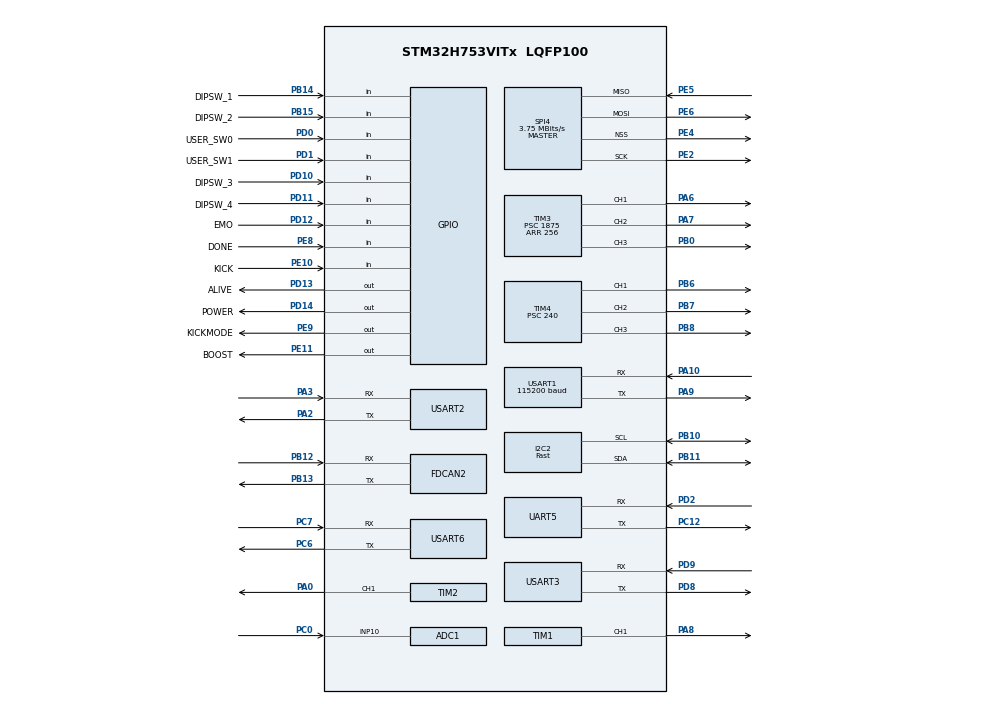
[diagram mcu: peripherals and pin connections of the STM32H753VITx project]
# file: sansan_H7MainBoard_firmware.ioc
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ADC1.Channel-3\#ChannelRegularConversion=ADC_CHANNEL_10
ADC1.ContinuousConvMode=DISABLE
ADC1.NbrOfConversionFlag=1
ADC1.OffsetNumber-3\#ChannelRegularConversion=ADC_OFFSET_NONE
ADC1.Rank-3\#ChannelRegularConversion=1
ADC1.Resolution=ADC_RESOLUTION_10B
ADC1.SamplingTime-3\#ChannelRegularConversion=ADC_SAMPLETIME_1CYCLE_5
ADC1.master=1
Dma.Request0=UART5_RX
Dma.UART5_RX.0.Direction=DMA_PERIPH_TO_MEMORY
Dma.UART5_RX.0.EventEnable=DISABLE
Dma.UART5_RX.0.FIFOMode=DMA_FIFOMODE_DISABLE
Dma.UART5_RX.0.Instance=DMA1_Stream0
Dma.UART5_RX.0.MemDataAlignment=DMA_MDATAALIGN_BYTE
Dma.UART5_RX.0.MemInc=DMA_MINC_ENABLE
Dma.UART5_RX.0.Mode=DMA_CIRCULAR
Dma.UART5_RX.0.PeriphDataAlignment=DMA_PDATAALIGN_BYTE
Dma.UART5_RX.0.PeriphInc=DMA_PINC_DISABLE
Dma.UART5_RX.0.Polarity=HAL_DMAMUX_REQ_GEN_RISING
Dma.UART5_RX.0.Priority=DMA_PRIORITY_LOW
Dma.UART5_RX.0.RequestNumber=1
Dma.UART5_RX.0.SignalID=NONE
Dma.UART5_RX.0.SyncEnable=DISABLE
Dma.UART5_RX.0.SyncPolarity=HAL_DMAMUX_SYNC_NO_EVENT
Dma.UART5_RX.0.SyncRequestNumber=1
Dma.UART5_RX.0.SyncSignalID=NONE
FDCAN2.DataPrescaler=8
FDCAN2.DataSyncJumpWidth=2
FDCAN2.DataTimeSeg1=6
FDCAN2.DataTimeSeg2=3
FDCAN2.MessageRAMOffset=500
FDCAN2.NominalPrescaler=8
FDCAN2.NominalSyncJumpWidth=2
FDCAN2.NominalTimeSeg1=6
FDCAN2.NominalTimeSeg2=3
FDCAN2.RxFifo0ElmtsNbr=32
FDCAN2.StdFiltersNbr=1
FDCAN2.TxBuffersNbr=16
FDCAN2.TxFifoQueueElmtsNbr=16
I2C2.I2C_Fall_Time=300
I2C2.I2C_Rise_Time=300
I2C2.I2C_Speed_Mode=I2C_Fast
I2C2.Timing=0x30B70F24
Mcu.Family=STM32H7
Mcu.Name=STM32H753VITx
Mcu.Package=LQFP100
NVIC.DMA1_Stream0_IRQn=true\:0\:0\:false\:false\:true\:false\:true\:true
NVIC.FDCAN2_IT0_IRQn=true\:1\:0\:true\:false\:true\:true\:true\:true
NVIC.FDCAN2_IT1_IRQn=true\:1\:0\:true\:false\:true\:true\:true\:true
NVIC.PriorityGroup=NVIC_PRIORITYGROUP_4
NVIC.SPI4_IRQn=true\:0\:0\:false\:false\:true\:true\:true\:true
NVIC.TIM8_BRK_TIM12_IRQn=true\:0\:0\:false\:false\:true\:true\:true\:true
NVIC.TIM8_UP_TIM13_IRQn=true\:2\:0\:true\:false\:true\:true\:true\:true
NVIC.UART5_IRQn=true\:3\:0\:true\:false\:true\:true\:true\:true
NVIC.USART1_IRQn=true\:0\:0\:false\:false\:true\:true\:true\:true
PA0.Signal=S_TIM2_CH1
PA10.Mode=Asynchronous
PA10.Signal=USART1_RX
PA13\ (JTMS/SWDIO).Mode=Trace_Asynchronous_SW
PA13\ (JTMS/SWDIO).Signal=DEBUG_JTMS-SWDIO
PA14\ (JTCK/SWCLK).Mode=Trace_Asynchronous_SW
PA14\ (JTCK/SWCLK).Signal=DEBUG_JTCK-SWCLK
PA2.Mode=Asynchronous
PA2.Signal=USART2_TX
PA3.Mode=Asynchronous
PA3.Signal=USART2_RX
PA6.Signal=S_TIM3_CH1
PA7.Signal=S_TIM3_CH2
PA8.Signal=S_TIM1_CH1
PA9.Mode=Asynchronous
PA9.Signal=USART1_TX
PB0.Signal=S_TIM3_CH3
PB10.Mode=I2C
PB10.Signal=I2C2_SCL
PB11.Mode=I2C
PB11.Signal=I2C2_SDA
PB12.Mode=FDCAN_Activate
PB12.Signal=FDCAN2_RX
PB13.Mode=FDCAN_Activate
PB13.Signal=FDCAN2_TX
PB14.GPIO_Label=DIPSW_1
PB14.GPIO_PuPd=GPIO_PULLUP
PB14.Signal=GPIO_Input
PB15.GPIO_Label=DIPSW_2
PB15.GPIO_PuPd=GPIO_PULLUP
PB15.Signal=GPIO_Input
PB3\ (JTDO/TRACESWO).Mode=Trace_Asynchronous_SW
PB3\ (JTDO/TRACESWO).Signal=DEBUG_JTDO-SWO
PB6.Signal=S_TIM4_CH1
PB7.Signal=S_TIM4_CH2
PB8.Signal=S_TIM4_CH3
PC0.Signal=ADCx_INP10
PC12.Mode=Asynchronous
PC12.Signal=UART5_TX
PC6.Mode=Asynchronous
PC6.Signal=USART6_TX
PC7.Mode=Asynchronous
PC7.Signal=USART6_RX
PD0.GPIO_Label=USER_SW0
PD0.GPIO_PuPd=GPIO_PULLUP
PD0.Signal=GPIO_Input
PD1.GPIO_Label=USER_SW1
PD1.GPIO_PuPd=GPIO_PULLUP
PD1.Signal=GPIO_Input
PD10.GPIO_Label=DIPSW_3
PD10.GPIO_PuPd=GPIO_PULLUP
PD10.Signal=GPIO_Input
PD11.GPIO_Label=DIPSW_4
PD11.GPIO_PuPd=GPIO_PULLUP
PD11.Signal=GPIO_Input
PD12.GPIO_Label=EMO
PD12.Signal=GPIO_Input
PD13.GPIO_Label=ALIVE
PD13.Signal=GPIO_Output
PD14.GPIO_Label=POWER
PD14.Signal=GPIO_Output
PD2.Mode=Asynchronous
PD2.Signal=UART5_RX
PD8.Mode=Asynchronous
PD8.Signal=USART3_TX
PD9.Mode=Asynchronous
PD9.Signal=USART3_RX
PE0.Signal=UART8_RX
PE1.Signal=UART8_TX
PE10.GPIO_Label=KICK
PE10.Signal=GPIO_Input
PE11.GPIO_Label=BOOST
PE11.Signal=GPIO_Output
PE2.Mode=Full_Duplex_Master
PE2.Signal=SPI4_SCK
PE4.GPIO_PuPd=GPIO_PULLUP
PE4.Mode=NSS_Signal_Hard_Output
PE4.Signal=SPI4_NSS
PE5.Mode=Full_Duplex_Master
PE5.Signal=SPI4_MISO
PE6.Mode=Full_Duplex_Master
PE6.Signal=SPI4_MOSI
PE8.GPIO_Label=DONE
PE8.Signal=GPIO_Input
PE9.GPIO_Label=KICKMODE
PE9.Signal=GPIO_Output
PH0-OSC_IN\ (PH0).Mode=HSE-External-Oscillator
PH0-OSC_IN\ (PH0).Signal=RCC_OSC_IN
PH1-OSC_OUT\ (PH1).Mode=HSE-External-Oscillator
PH1-OSC_OUT\ (PH1).Signal=RCC_OSC_OUT
ProjectManager.HeapSize=0x200
ProjectManager.StackSize=0x400
ProjectManager.TargetToolchain=STM32CubeIDE
RCC.ADCFreq_Value=80000000
RCC.APB1Freq_Value=120000000
RCC.APB2Freq_Value=120000000
RCC.APB3Freq_Value=120000000
RCC.APB4Freq_Value=120000000
RCC.CortexFreq_Value=480000000
RCC.D1PPRE=RCC_APB3_DIV2
RCC.D2PPRE1=RCC_APB1_DIV2
RCC.D2PPRE2=RCC_APB2_DIV2
RCC.D3PPRE=RCC_APB4_DIV2
RCC.DIVM1=8
RCC.DIVM2=8
RCC.DIVN1=480
RCC.DIVN2=80
RCC.DIVQ3=4
RCC.DIVR3=4
RCC.FDCANCLockSelection=RCC_FDCANCLKSOURCE_PLL2
RCC.HCLKFreq_Value=240000000
RCC.HPRE=RCC_HCLK_DIV2
RCC.HSE_VALUE=16000000
RCC.PLLFRACN=0
RCC.PLLSourceVirtual=RCC_PLLSOURCE_HSE
RCC.ProductRev=revV
RCC.SYSCLKFreq_VALUE=480000000
RCC.SYSCLKSource=RCC_SYSCLKSOURCE_PLLCLK
RCC.USBFreq_Value=480000000
SH.ADCx_INP10.0=ADC1_INP10,IN10-Single-Ended
SH.S_TIM1_CH1.0=TIM1_CH1,PWM Generation1 CH1
SH.S_TIM2_CH1.0=TIM2_CH1,PWM Generation1 CH1
SH.S_TIM3_CH1.0=TIM3_CH1,PWM Generation1 CH1
SH.S_TIM3_CH2.0=TIM3_CH2,PWM Generation2 CH2
SH.S_TIM3_CH3.0=TIM3_CH3,PWM Generation3 CH3
SH.S_TIM4_CH1.0=TIM4_CH1,PWM Generation1 CH1
SH.S_TIM4_CH2.0=TIM4_CH2,PWM Generation2 CH2
SH.S_TIM4_CH3.0=TIM4_CH3,PWM Generation3 CH3
SPI4.BaudRatePrescaler=SPI_BAUDRATEPRESCALER_32
SPI4.CalculateBaudRate=3.75 MBits/s
SPI4.DataSize=SPI_DATASIZE_8BIT
SPI4.Direction=SPI_DIRECTION_2LINES
SPI4.Mode=SPI_MODE_MASTER
SPI4.VirtualNSS=VM_NSSHARD
SPI4.VirtualType=VM_MASTER
TIM1.Channel-PWM\ Generation1\ CH1=TIM_CHANNEL_1
TIM1.Period=10000
TIM1.Prescaler=480
TIM1.Pulse-PWM\ Generation1\ CH1=0
TIM12.Period=240
TIM12.Prescaler=1000
TIM13.Period=2400
TIM13.Prescaler=1000
TIM2.Channel-PWM\ Generation1\ CH1=TIM_CHANNEL_1
TIM3.AutoReloadPreload=TIM_AUTORELOAD_PRELOAD_ENABLE
TIM3.Channel-PWM\ Generation1\ CH1=TIM_CHANNEL_1
TIM3.Channel-PWM\ Generation2\ CH2=TIM_CHANNEL_2
TIM3.Channel-PWM\ Generation3\ CH3=TIM_CHANNEL_3
TIM3.Period=256
TIM3.Prescaler=1875
TIM3.Pulse-PWM\ Generation1\ CH1=0
TIM3.Pulse-PWM\ Generation2\ CH2=0
TIM3.Pulse-PWM\ Generation3\ CH3=0
TIM4.Channel-PWM\ Generation1\ CH1=TIM_CHANNEL_1
TIM4.Channel-PWM\ Generation2\ CH2=TIM_CHANNEL_2
TIM4.Channel-PWM\ Generation3\ CH3=TIM_CHANNEL_3
TIM4.OC1Preload_PWM=ENABLE
TIM4.Prescaler=240
TIM4.Pulse-PWM\ Generation1\ CH1=0
USART1.BaudRate=115200
USART1.VirtualMode-Asynchronous=VM_ASYNC
USART2.VirtualMode-Asynchronous=VM_ASYNC
USART3.VirtualMode-Asynchronous=VM_ASYNC
USART6.FIFOMode=FIFOMODE_ENABLE
USART6.VirtualMode=VM_ASYNC
VP_TIM12_VS_ClockSourceINT.Mode=Internal
VP_TIM13_VS_ClockSourceINT.Mode=Enable_Timer
VP_TIM1_VS_ClockSourceINT.Mode=Internal
VP_TIM2_VS_ClockSourceINT.Mode=Internal
VP_TIM4_VS_ClockSourceINT.Mode=Internal
board=custom

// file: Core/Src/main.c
/* USER CODE BEGIN Header */
/**
  ******************************************************************************
  * @file           : main.c
  * @brief          : Main program body
  ******************************************************************************
  * @attention
  *
  * <h2><center>&copy; Copyright (c) 2020 STMicroelectronics.
  * All rights reserved.</center></h2>
  *
  * This software component is licensed by ST under BSD 3-Clause license,
  * the "License"; You may not use this file except in compliance with the
  * License. You may obtain a copy of the License at:
  *                        opensource.org/licenses/BSD-3-Clause
  *
  ******************************************************************************
  */
/* USER CODE END Header */
#include "main.h"

/* USER CODE BEGIN Includes */

#include <stdio.h>

#include "cppWrapper.hpp"

/* USER CODE END Includes */

ADC_HandleTypeDef hadc1;

FDCAN_HandleTypeDef hfdcan2;

I2C_HandleTypeDef hi2c2;

SPI_HandleTypeDef hspi4;

TIM_HandleTypeDef htim1;
TIM_HandleTypeDef htim2;
TIM_HandleTypeDef htim3;
TIM_HandleTypeDef htim4;
TIM_HandleTypeDef htim12;
TIM_HandleTypeDef htim13;

UART_HandleTypeDef huart5;
UART_HandleTypeDef huart1;
UART_HandleTypeDef huart2;
UART_HandleTypeDef huart3;
UART_HandleTypeDef huart6;
DMA_HandleTypeDef hdma_uart5_rx;
DMA_HandleTypeDef hdma_usart1_rx;

void SystemClock_Config(void);
void PeriphCommonClock_Config(void);
static void MX_GPIO_Init(void);
static void MX_DMA_Init(void);
static void MX_ADC1_Init(void);
static void MX_I2C2_Init(void);
static void MX_SPI4_Init(void);
static void MX_TIM1_Init(void);
static void MX_TIM2_Init(void);
static void MX_TIM3_Init(void);
static void MX_TIM4_Init(void);
static void MX_USART1_UART_Init(void);
static void MX_USART2_UART_Init(void);
static void MX_USART3_UART_Init(void);
static void MX_USART6_UART_Init(void);
static void MX_FDCAN2_Init(void);
static void MX_UART5_Init(void);
static void MX_TIM12_Init(void);
static void MX_TIM13_Init(void);

/* USER CODE BEGIN 0 */

#ifdef __GNUC__
#define PUTCHAR_PROTOTYPE int __io_putchar(int ch)
#else
#define PUTCHAR_PROTOTYPE int fputc(int ch, FILE *f)
#endif /* __GNUC__ */
void __io_putchar(uint8_t ch)
{
	HAL_UART_Transmit(&huart6, &ch, 1, 1);
}

/* USER CODE END 0 */

int main(void)
{

  /* MCU Configuration--------------------------------------------------------*/

  /* Reset of all peripherals, Initializes the Flash interface and the Systick. */
  HAL_Init();

  /* Configure the system clock */
  SystemClock_Config();

/* Configure the peripherals common clocks */
  PeriphCommonClock_Config();

  /* Initialize all configured peripherals */
  MX_GPIO_Init();
  MX_DMA_Init();
  MX_ADC1_Init();
  MX_I2C2_Init();
  MX_SPI4_Init();
  MX_TIM1_Init();
  MX_TIM2_Init();
  MX_TIM3_Init();
  MX_TIM4_Init();
  MX_USART1_UART_Init();
  MX_USART2_UART_Init();
  MX_USART3_UART_Init();
  MX_USART6_UART_Init();
  MX_FDCAN2_Init();
  MX_UART5_Init();
  MX_TIM12_Init();
  MX_TIM13_Init();
  /* USER CODE BEGIN 2 */

  cppMain();

  /* USER CODE END 2 */

  /* Infinite loop */
  while (1)
  {

  }
}

void SystemClock_Config(void)
{
  RCC_OscInitTypeDef RCC_OscInitStruct = {0};
  RCC_ClkInitTypeDef RCC_ClkInitStruct = {0};

  /** Supply configuration update enable
  */
  HAL_PWREx_ConfigSupply(PWR_LDO_SUPPLY);
  /** Configure the main internal regulator output voltage
  */
  __HAL_PWR_VOLTAGESCALING_CONFIG(PWR_REGULATOR_VOLTAGE_SCALE0);

  while(!__HAL_PWR_GET_FLAG(PWR_FLAG_VOSRDY)) {}
  /** Macro to configure the PLL clock source
  */
  __HAL_RCC_PLL_PLLSOURCE_CONFIG(RCC_PLLSOURCE_HSE);
  /** Initializes the RCC Oscillators according to the specified parameters
  * in the RCC_OscInitTypeDef structure.
  */
  RCC_OscInitStruct.OscillatorType = RCC_OSCILLATORTYPE_HSE;
  RCC_OscInitStruct.HSEState = RCC_HSE_ON;
  RCC_OscInitStruct.PLL.PLLState = RCC_PLL_ON;
  RCC_OscInitStruct.PLL.PLLSource = RCC_PLLSOURCE_HSE;
  RCC_OscInitStruct.PLL.PLLM = 8;
  RCC_OscInitStruct.PLL.PLLN = 480;
  RCC_OscInitStruct.PLL.PLLP = 2;
  RCC_OscInitStruct.PLL.PLLQ = 2;
  RCC_OscInitStruct.PLL.PLLR = 2;
  RCC_OscInitStruct.PLL.PLLRGE = RCC_PLL1VCIRANGE_1;
  RCC_OscInitStruct.PLL.PLLVCOSEL = RCC_PLL1VCOWIDE;
  RCC_OscInitStruct.PLL.PLLFRACN = 0;
  if (HAL_RCC_OscConfig(&RCC_OscInitStruct) != HAL_OK)
  {
    Error_Handler();
  }
  /** Initializes the CPU, AHB and APB buses clocks
  */
  RCC_ClkInitStruct.ClockType = RCC_CLOCKTYPE_HCLK|RCC_CLOCKTYPE_SYSCLK
                              |RCC_CLOCKTYPE_PCLK1|RCC_CLOCKTYPE_PCLK2
                              |RCC_CLOCKTYPE_D3PCLK1|RCC_CLOCKTYPE_D1PCLK1;
  RCC_ClkInitStruct.SYSCLKSource = RCC_SYSCLKSOURCE_PLLCLK;
  RCC_ClkInitStruct.SYSCLKDivider = RCC_SYSCLK_DIV1;
  RCC_ClkInitStruct.AHBCLKDivider = RCC_HCLK_DIV2;
  RCC_ClkInitStruct.APB3CLKDivider = RCC_APB3_DIV2;
  RCC_ClkInitStruct.APB1CLKDivider = RCC_APB1_DIV2;
  RCC_ClkInitStruct.APB2CLKDivider = RCC_APB2_DIV2;
  RCC_ClkInitStruct.APB4CLKDivider = RCC_APB4_DIV2;

  if (HAL_RCC_ClockConfig(&RCC_ClkInitStruct, FLASH_LATENCY_4) != HAL_OK)
  {
    Error_Handler();
  }
}

void PeriphCommonClock_Config(void)
{
  RCC_PeriphCLKInitTypeDef PeriphClkInitStruct = {0};

  /** Initializes the peripherals clock
  */
  PeriphClkInitStruct.PeriphClockSelection = RCC_PERIPHCLK_ADC|RCC_PERIPHCLK_FDCAN;
  PeriphClkInitStruct.PLL2.PLL2M = 8;
  PeriphClkInitStruct.PLL2.PLL2N = 80;
  PeriphClkInitStruct.PLL2.PLL2P = 2;
  PeriphClkInitStruct.PLL2.PLL2Q = 2;
  PeriphClkInitStruct.PLL2.PLL2R = 2;
  PeriphClkInitStruct.PLL2.PLL2RGE = RCC_PLL2VCIRANGE_1;
  PeriphClkInitStruct.PLL2.PLL2VCOSEL = RCC_PLL2VCOMEDIUM;
  PeriphClkInitStruct.PLL2.PLL2FRACN = 0;
  PeriphClkInitStruct.FdcanClockSelection = RCC_FDCANCLKSOURCE_PLL2;
  PeriphClkInitStruct.AdcClockSelection = RCC_ADCCLKSOURCE_PLL2;
  if (HAL_RCCEx_PeriphCLKConfig(&PeriphClkInitStruct) != HAL_OK)
  {
    Error_Handler();
  }
}

static void MX_ADC1_Init(void)
{

  ADC_MultiModeTypeDef multimode = {0};
  ADC_ChannelConfTypeDef sConfig = {0};

  /** Common config
  */
  hadc1.Instance = ADC1;
  hadc1.Init.ClockPrescaler = ADC_CLOCK_ASYNC_DIV1;
  hadc1.Init.Resolution = ADC_RESOLUTION_10B;
  hadc1.Init.ScanConvMode = ADC_SCAN_DISABLE;
  hadc1.Init.EOCSelection = ADC_EOC_SINGLE_CONV;
  hadc1.Init.LowPowerAutoWait = DISABLE;
  hadc1.Init.ContinuousConvMode = DISABLE;
  hadc1.Init.NbrOfConversion = 1;
  hadc1.Init.DiscontinuousConvMode = DISABLE;
  hadc1.Init.ExternalTrigConv = ADC_SOFTWARE_START;
  hadc1.Init.ExternalTrigConvEdge = ADC_EXTERNALTRIGCONVEDGE_NONE;
  hadc1.Init.ConversionDataManagement = ADC_CONVERSIONDATA_DR;
  hadc1.Init.Overrun = ADC_OVR_DATA_PRESERVED;
  hadc1.Init.LeftBitShift = ADC_LEFTBITSHIFT_NONE;
  hadc1.Init.OversamplingMode = DISABLE;
  if (HAL_ADC_Init(&hadc1) != HAL_OK)
  {
    Error_Handler();
  }
  /** Configure the ADC multi-mode
  */
  multimode.Mode = ADC_MODE_INDEPENDENT;
  if (HAL_ADCEx_MultiModeConfigChannel(&hadc1, &multimode) != HAL_OK)
  {
    Error_Handler();
  }
  /** Configure Regular Channel
  */
  sConfig.Channel = ADC_CHANNEL_10;
  sConfig.Rank = ADC_REGULAR_RANK_1;
  sConfig.SamplingTime = ADC_SAMPLETIME_1CYCLE_5;
  sConfig.SingleDiff = ADC_SINGLE_ENDED;
  sConfig.OffsetNumber = ADC_OFFSET_NONE;
  sConfig.Offset = 0;
  if (HAL_ADC_ConfigChannel(&hadc1, &sConfig) != HAL_OK)
  {
    Error_Handler();
  }

}

static void MX_FDCAN2_Init(void)
{

  hfdcan2.Instance = FDCAN2;
  hfdcan2.Init.FrameFormat = FDCAN_FRAME_CLASSIC;
  hfdcan2.Init.Mode = FDCAN_MODE_NORMAL;
  hfdcan2.Init.AutoRetransmission = DISABLE;
  hfdcan2.Init.TransmitPause = DISABLE;
  hfdcan2.Init.ProtocolException = DISABLE;
  hfdcan2.Init.NominalPrescaler = 8;
  hfdcan2.Init.NominalSyncJumpWidth = 2;
  hfdcan2.Init.NominalTimeSeg1 = 6;
  hfdcan2.Init.NominalTimeSeg2 = 3;
  hfdcan2.Init.DataPrescaler = 8;
  hfdcan2.Init.DataSyncJumpWidth = 2;
  hfdcan2.Init.DataTimeSeg1 = 6;
  hfdcan2.Init.DataTimeSeg2 = 3;
  hfdcan2.Init.MessageRAMOffset = 500;
  hfdcan2.Init.StdFiltersNbr = 1;
  hfdcan2.Init.ExtFiltersNbr = 0;
  hfdcan2.Init.RxFifo0ElmtsNbr = 32;
  hfdcan2.Init.RxFifo0ElmtSize = FDCAN_DATA_BYTES_8;
  hfdcan2.Init.RxFifo1ElmtsNbr = 0;
  hfdcan2.Init.RxFifo1ElmtSize = FDCAN_DATA_BYTES_8;
  hfdcan2.Init.RxBuffersNbr = 0;
  hfdcan2.Init.RxBufferSize = FDCAN_DATA_BYTES_8;
  hfdcan2.Init.TxEventsNbr = 0;
  hfdcan2.Init.TxBuffersNbr = 16;
  hfdcan2.Init.TxFifoQueueElmtsNbr = 16;
  hfdcan2.Init.TxFifoQueueMode = FDCAN_TX_FIFO_OPERATION;
  hfdcan2.Init.TxElmtSize = FDCAN_DATA_BYTES_8;
  if (HAL_FDCAN_Init(&hfdcan2) != HAL_OK)
  {
    Error_Handler();
  }

}

static void MX_I2C2_Init(void)
{

  hi2c2.Instance = I2C2;
  hi2c2.Init.Timing = 0x30B70F24;
  hi2c2.Init.OwnAddress1 = 0;
  hi2c2.Init.AddressingMode = I2C_ADDRESSINGMODE_7BIT;
  hi2c2.Init.DualAddressMode = I2C_DUALADDRESS_DISABLE;
  hi2c2.Init.OwnAddress2 = 0;
  hi2c2.Init.OwnAddress2Masks = I2C_OA2_NOMASK;
  hi2c2.Init.GeneralCallMode = I2C_GENERALCALL_DISABLE;
  hi2c2.Init.NoStretchMode = I2C_NOSTRETCH_DISABLE;
  if (HAL_I2C_Init(&hi2c2) != HAL_OK)
  {
    Error_Handler();
  }
  /** Configure Analogue filter
  */
  if (HAL_I2CEx_ConfigAnalogFilter(&hi2c2, I2C_ANALOGFILTER_ENABLE) != HAL_OK)
  {
    Error_Handler();
  }
  /** Configure Digital filter
  */
  if (HAL_I2CEx_ConfigDigitalFilter(&hi2c2, 0) != HAL_OK)
  {
    Error_Handler();
  }

}

static void MX_SPI4_Init(void)
{

  /* SPI4 parameter configuration*/
  hspi4.Instance = SPI4;
  hspi4.Init.Mode = SPI_MODE_MASTER;
  hspi4.Init.Direction = SPI_DIRECTION_2LINES;
  hspi4.Init.DataSize = SPI_DATASIZE_8BIT;
  hspi4.Init.CLKPolarity = SPI_POLARITY_LOW;
  hspi4.Init.CLKPhase = SPI_PHASE_1EDGE;
  hspi4.Init.NSS = SPI_NSS_HARD_OUTPUT;
  hspi4.Init.BaudRatePrescaler = SPI_BAUDRATEPRESCALER_32;
  hspi4.Init.FirstBit = SPI_FIRSTBIT_MSB;
  hspi4.Init.TIMode = SPI_TIMODE_DISABLE;
  hspi4.Init.CRCCalculation = SPI_CRCCALCULATION_DISABLE;
  hspi4.Init.CRCPolynomial = 0x0;
  hspi4.Init.NSSPMode = SPI_NSS_PULSE_ENABLE;
  hspi4.Init.NSSPolarity = SPI_NSS_POLARITY_LOW;
  hspi4.Init.FifoThreshold = SPI_FIFO_THRESHOLD_01DATA;
  hspi4.Init.TxCRCInitializationPattern = SPI_CRC_INITIALIZATION_ALL_ZERO_PATTERN;
  hspi4.Init.RxCRCInitializationPattern = SPI_CRC_INITIALIZATION_ALL_ZERO_PATTERN;
  hspi4.Init.MasterSSIdleness = SPI_MASTER_SS_IDLENESS_00CYCLE;
  hspi4.Init.MasterInterDataIdleness = SPI_MASTER_INTERDATA_IDLENESS_00CYCLE;
  hspi4.Init.MasterReceiverAutoSusp = SPI_MASTER_RX_AUTOSUSP_DISABLE;
  hspi4.Init.MasterKeepIOState = SPI_MASTER_KEEP_IO_STATE_DISABLE;
  hspi4.Init.IOSwap = SPI_IO_SWAP_DISABLE;
  if (HAL_SPI_Init(&hspi4) != HAL_OK)
  {
    Error_Handler();
  }

}

static void MX_TIM1_Init(void)
{

  TIM_ClockConfigTypeDef sClockSourceConfig = {0};
  TIM_MasterConfigTypeDef sMasterConfig = {0};
  TIM_OC_InitTypeDef sConfigOC = {0};
  TIM_BreakDeadTimeConfigTypeDef sBreakDeadTimeConfig = {0};

  htim1.Instance = TIM1;
  htim1.Init.Prescaler = 480;
  htim1.Init.CounterMode = TIM_COUNTERMODE_UP;
  htim1.Init.Period = 10000;
  htim1.Init.ClockDivision = TIM_CLOCKDIVISION_DIV1;
  htim1.Init.RepetitionCounter = 0;
  htim1.Init.AutoReloadPreload = TIM_AUTORELOAD_PRELOAD_DISABLE;
  if (HAL_TIM_Base_Init(&htim1) != HAL_OK)
  {
    Error_Handler();
  }
  sClockSourceConfig.ClockSource = TIM_CLOCKSOURCE_INTERNAL;
  if (HAL_TIM_ConfigClockSource(&htim1, &sClockSourceConfig) != HAL_OK)
  {
    Error_Handler();
  }
  if (HAL_TIM_PWM_Init(&htim1) != HAL_OK)
  {
    Error_Handler();
  }
  sMasterConfig.MasterOutputTrigger = TIM_TRGO_RESET;
  sMasterConfig.MasterOutputTrigger2 = TIM_TRGO2_RESET;
  sMasterConfig.MasterSlaveMode = TIM_MASTERSLAVEMODE_DISABLE;
  if (HAL_TIMEx_MasterConfigSynchronization(&htim1, &sMasterConfig) != HAL_OK)
  {
    Error_Handler();
  }
  sConfigOC.OCMode = TIM_OCMODE_PWM1;
  sConfigOC.Pulse = 0;
  sConfigOC.OCPolarity = TIM_OCPOLARITY_HIGH;
  sConfigOC.OCNPolarity = TIM_OCNPOLARITY_HIGH;
  sConfigOC.OCFastMode = TIM_OCFAST_DISABLE;
  sConfigOC.OCIdleState = TIM_OCIDLESTATE_RESET;
  sConfigOC.OCNIdleState = TIM_OCNIDLESTATE_RESET;
  if (HAL_TIM_PWM_ConfigChannel(&htim1, &sConfigOC, TIM_CHANNEL_1) != HAL_OK)
  {
    Error_Handler();
  }
  sBreakDeadTimeConfig.OffStateRunMode = TIM_OSSR_DISABLE;
  sBreakDeadTimeConfig.OffStateIDLEMode = TIM_OSSI_DISABLE;
  sBreakDeadTimeConfig.LockLevel = TIM_LOCKLEVEL_OFF;
  sBreakDeadTimeConfig.DeadTime = 0;
  sBreakDeadTimeConfig.BreakState = TIM_BREAK_DISABLE;
  sBreakDeadTimeConfig.BreakPolarity = TIM_BREAKPOLARITY_HIGH;
  sBreakDeadTimeConfig.BreakFilter = 0;
  sBreakDeadTimeConfig.Break2State = TIM_BREAK2_DISABLE;
  sBreakDeadTimeConfig.Break2Polarity = TIM_BREAK2POLARITY_HIGH;
  sBreakDeadTimeConfig.Break2Filter = 0;
  sBreakDeadTimeConfig.AutomaticOutput = TIM_AUTOMATICOUTPUT_DISABLE;
  if (HAL_TIMEx_ConfigBreakDeadTime(&htim1, &sBreakDeadTimeConfig) != HAL_OK)
  {
    Error_Handler();
  }
  HAL_TIM_MspPostInit(&htim1);

}

static void MX_TIM2_Init(void)
{

  TIM_ClockConfigTypeDef sClockSourceConfig = {0};
  TIM_MasterConfigTypeDef sMasterConfig = {0};
  TIM_OC_InitTypeDef sConfigOC = {0};

  htim2.Instance = TIM2;
  htim2.Init.Prescaler = 0;
  htim2.Init.CounterMode = TIM_COUNTERMODE_UP;
  htim2.Init.Period = 4294967295;
  htim2.Init.ClockDivision = TIM_CLOCKDIVISION_DIV1;
  htim2.Init.AutoReloadPreload = TIM_AUTORELOAD_PRELOAD_DISABLE;
  if (HAL_TIM_Base_Init(&htim2) != HAL_OK)
  {
    Error_Handler();
  }
  sClockSourceConfig.ClockSource = TIM_CLOCKSOURCE_INTERNAL;
  if (HAL_TIM_ConfigClockSource(&htim2, &sClockSourceConfig) != HAL_OK)
  {
    Error_Handler();
  }
  if (HAL_TIM_PWM_Init(&htim2) != HAL_OK)
  {
    Error_Handler();
  }
  sMasterConfig.MasterOutputTrigger = TIM_TRGO_RESET;
  sMasterConfig.MasterSlaveMode = TIM_MASTERSLAVEMODE_DISABLE;
  if (HAL_TIMEx_MasterConfigSynchronization(&htim2, &sMasterConfig) != HAL_OK)
  {
    Error_Handler();
  }
  sConfigOC.OCMode = TIM_OCMODE_PWM1;
  sConfigOC.Pulse = 0;
  sConfigOC.OCPolarity = TIM_OCPOLARITY_HIGH;
  sConfigOC.OCFastMode = TIM_OCFAST_DISABLE;
  if (HAL_TIM_PWM_ConfigChannel(&htim2, &sConfigOC, TIM_CHANNEL_1) != HAL_OK)
  {
    Error_Handler();
  }
  HAL_TIM_MspPostInit(&htim2);

}

static void MX_TIM3_Init(void)
{

  TIM_MasterConfigTypeDef sMasterConfig = {0};
  TIM_OC_InitTypeDef sConfigOC = {0};

  htim3.Instance = TIM3;
  htim3.Init.Prescaler = 1875;
  htim3.Init.CounterMode = TIM_COUNTERMODE_UP;
  htim3.Init.Period = 256;
  htim3.Init.ClockDivision = TIM_CLOCKDIVISION_DIV1;
  htim3.Init.AutoReloadPreload = TIM_AUTORELOAD_PRELOAD_ENABLE;
  if (HAL_TIM_PWM_Init(&htim3) != HAL_OK)
  {
    Error_Handler();
  }
  sMasterConfig.MasterOutputTrigger = TIM_TRGO_RESET;
  sMasterConfig.MasterSlaveMode = TIM_MASTERSLAVEMODE_DISABLE;
  if (HAL_TIMEx_MasterConfigSynchronization(&htim3, &sMasterConfig) != HAL_OK)
  {
    Error_Handler();
  }
  sConfigOC.OCMode = TIM_OCMODE_PWM1;
  sConfigOC.Pulse = 0;
  sConfigOC.OCPolarity = TIM_OCPOLARITY_HIGH;
  sConfigOC.OCFastMode = TIM_OCFAST_DISABLE;
  if (HAL_TIM_PWM_ConfigChannel(&htim3, &sConfigOC, TIM_CHANNEL_1) != HAL_OK)
  {
    Error_Handler();
  }
  if (HAL_TIM_PWM_ConfigChannel(&htim3, &sConfigOC, TIM_CHANNEL_2) != HAL_OK)
  {
    Error_Handler();
  }
  if (HAL_TIM_PWM_ConfigChannel(&htim3, &sConfigOC, TIM_CHANNEL_3) != HAL_OK)
  {
    Error_Handler();
  }
  HAL_TIM_MspPostInit(&htim3);

}

static void MX_TIM4_Init(void)
{

  TIM_ClockConfigTypeDef sClockSourceConfig = {0};
  TIM_MasterConfigTypeDef sMasterConfig = {0};
  TIM_OC_InitTypeDef sConfigOC = {0};

  htim4.Instance = TIM4;
  htim4.Init.Prescaler = 240;
  htim4.Init.CounterMode = TIM_COUNTERMODE_UP;
  htim4.Init.Period = 65535;
  htim4.Init.ClockDivision = TIM_CLOCKDIVISION_DIV1;
  htim4.Init.AutoReloadPreload = TIM_AUTORELOAD_PRELOAD_DISABLE;
  if (HAL_TIM_Base_Init(&htim4) != HAL_OK)
  {
    Error_Handler();
  }
  sClockSourceConfig.ClockSource = TIM_CLOCKSOURCE_INTERNAL;
  if (HAL_TIM_ConfigClockSource(&htim4, &sClockSourceConfig) != HAL_OK)
  {
    Error_Handler();
  }
  if (HAL_TIM_PWM_Init(&htim4) != HAL_OK)
  {
    Error_Handler();
  }
  sMasterConfig.MasterOutputTrigger = TIM_TRGO_RESET;
  sMasterConfig.MasterSlaveMode = TIM_MASTERSLAVEMODE_DISABLE;
  if (HAL_TIMEx_MasterConfigSynchronization(&htim4, &sMasterConfig) != HAL_OK)
  {
    Error_Handler();
  }
  sConfigOC.OCMode = TIM_OCMODE_PWM1;
  sConfigOC.Pulse = 0;
  sConfigOC.OCPolarity = TIM_OCPOLARITY_HIGH;
  sConfigOC.OCFastMode = TIM_OCFAST_DISABLE;
  if (HAL_TIM_PWM_ConfigChannel(&htim4, &sConfigOC, TIM_CHANNEL_1) != HAL_OK)
  {
    Error_Handler();
  }
  if (HAL_TIM_PWM_ConfigChannel(&htim4, &sConfigOC, TIM_CHANNEL_2) != HAL_OK)
  {
    Error_Handler();
  }
  if (HAL_TIM_PWM_ConfigChannel(&htim4, &sConfigOC, TIM_CHANNEL_3) != HAL_OK)
  {
    Error_Handler();
  }
  HAL_TIM_MspPostInit(&htim4);

}

static void MX_TIM12_Init(void)
{

  TIM_ClockConfigTypeDef sClockSourceConfig = {0};

  htim12.Instance = TIM12;
  htim12.Init.Prescaler = 1000;
  htim12.Init.CounterMode = TIM_COUNTERMODE_UP;
  htim12.Init.Period = 240;
  htim12.Init.ClockDivision = TIM_CLOCKDIVISION_DIV1;
  htim12.Init.AutoReloadPreload = TIM_AUTORELOAD_PRELOAD_DISABLE;
  if (HAL_TIM_Base_Init(&htim12) != HAL_OK)
  {
    Error_Handler();
  }
  sClockSourceConfig.ClockSource = TIM_CLOCKSOURCE_INTERNAL;
  if (HAL_TIM_ConfigClockSource(&htim12, &sClockSourceConfig) != HAL_OK)
  {
    Error_Handler();
  }

}

static void MX_TIM13_Init(void)
{

  htim13.Instance = TIM13;
  htim13.Init.Prescaler = 1000;
  htim13.Init.CounterMode = TIM_COUNTERMODE_UP;
  htim13.Init.Period = 2400;
  htim13.Init.ClockDivision = TIM_CLOCKDIVISION_DIV1;
  htim13.Init.AutoReloadPreload = TIM_AUTORELOAD_PRELOAD_DISABLE;
  if (HAL_TIM_Base_Init(&htim13) != HAL_OK)
  {
    Error_Handler();
  }

}

static void MX_UART5_Init(void)
{

  huart5.Instance = UART5;
  huart5.Init.BaudRate = 115200;
  huart5.Init.WordLength = UART_WORDLENGTH_8B;
  huart5.Init.StopBits = UART_STOPBITS_1;
  huart5.Init.Parity = UART_PARITY_NONE;
  huart5.Init.Mode = UART_MODE_TX_RX;
  huart5.Init.HwFlowCtl = UART_HWCONTROL_NONE;
  huart5.Init.OverSampling = UART_OVERSAMPLING_16;
  huart5.Init.OneBitSampling = UART_ONE_BIT_SAMPLE_DISABLE;
  huart5.Init.ClockPrescaler = UART_PRESCALER_DIV1;
  huart5.AdvancedInit.AdvFeatureInit = UART_ADVFEATURE_NO_INIT;
  if (HAL_UART_Init(&huart5) != HAL_OK)
  {
    Error_Handler();
  }
  if (HAL_UARTEx_SetTxFifoThreshold(&huart5, UART_TXFIFO_THRESHOLD_1_8) != HAL_OK)
  {
    Error_Handler();
  }
  if (HAL_UARTEx_SetRxFifoThreshold(&huart5, UART_RXFIFO_THRESHOLD_1_8) != HAL_OK)
  {
    Error_Handler();
  }
  if (HAL_UARTEx_DisableFifoMode(&huart5) != HAL_OK)
  {
    Error_Handler();
  }

}

static void MX_USART1_UART_Init(void)
{

  huart1.Instance = USART1;
  huart1.Init.BaudRate = 115200;
  huart1.Init.WordLength = UART_WORDLENGTH_8B;
  huart1.Init.StopBits = UART_STOPBITS_1;
  huart1.Init.Parity = UART_PARITY_NONE;
  huart1.Init.Mode = UART_MODE_TX_RX;
  huart1.Init.HwFlowCtl = UART_HWCONTROL_NONE;
  huart1.Init.OverSampling = UART_OVERSAMPLING_16;
  huart1.Init.OneBitSampling = UART_ONE_BIT_SAMPLE_DISABLE;
  huart1.Init.ClockPrescaler = UART_PRESCALER_DIV1;
  huart1.AdvancedInit.AdvFeatureInit = UART_ADVFEATURE_SWAP_INIT;
  huart1.AdvancedInit.Swap = UART_ADVFEATURE_SWAP_ENABLE;
  if (HAL_UART_Init(&huart1) != HAL_OK)
  {
    Error_Handler();
  }
  if (HAL_UARTEx_SetTxFifoThreshold(&huart1, UART_TXFIFO_THRESHOLD_1_8) != HAL_OK)
  {
    Error_Handler();
  }
  if (HAL_UARTEx_SetRxFifoThreshold(&huart1, UART_RXFIFO_THRESHOLD_1_8) != HAL_OK)
  {
    Error_Handler();
  }
  if (HAL_UARTEx_DisableFifoMode(&huart1) != HAL_OK)
  {
    Error_Handler();
  }

}

static void MX_USART2_UART_Init(void)
{

  huart2.Instance = USART2;
  huart2.Init.BaudRate = 115200;
  huart2.Init.WordLength = UART_WORDLENGTH_8B;
  huart2.Init.StopBits = UART_STOPBITS_1;
  huart2.Init.Parity = UART_PARITY_NONE;
  huart2.Init.Mode = UART_MODE_TX_RX;
  huart2.Init.HwFlowCtl = UART_HWCONTROL_NONE;
  huart2.Init.OverSampling = UART_OVERSAMPLING_16;
  huart2.Init.OneBitSampling = UART_ONE_BIT_SAMPLE_DISABLE;
  huart2.Init.ClockPrescaler = UART_PRESCALER_DIV1;
  huart2.AdvancedInit.AdvFeatureInit = UART_ADVFEATURE_NO_INIT;
  if (HAL_UART_Init(&huart2) != HAL_OK)
  {
    Error_Handler();
  }
  if (HAL_UARTEx_SetTxFifoThreshold(&huart2, UART_TXFIFO_THRESHOLD_1_8) != HAL_OK)
  {
    Error_Handler();
  }
  if (HAL_UARTEx_SetRxFifoThreshold(&huart2, UART_RXFIFO_THRESHOLD_1_8) != HAL_OK)
  {
    Error_Handler();
  }
  if (HAL_UARTEx_DisableFifoMode(&huart2) != HAL_OK)
  {
    Error_Handler();
  }

}

static void MX_USART3_UART_Init(void)
{

  huart3.Instance = USART3;
  huart3.Init.BaudRate = 115200;
  huart3.Init.WordLength = UART_WORDLENGTH_8B;
  huart3.Init.StopBits = UART_STOPBITS_1;
  huart3.Init.Parity = UART_PARITY_NONE;
  huart3.Init.Mode = UART_MODE_TX_RX;
  huart3.Init.HwFlowCtl = UART_HWCONTROL_NONE;
  huart3.Init.OverSampling = UART_OVERSAMPLING_16;
  huart3.Init.OneBitSampling = UART_ONE_BIT_SAMPLE_DISABLE;
  huart3.Init.ClockPrescaler = UART_PRESCALER_DIV1;
  huart3.AdvancedInit.AdvFeatureInit = UART_ADVFEATURE_NO_INIT;
  if (HAL_UART_Init(&huart3) != HAL_OK)
  {
    Error_Handler();
  }
  if (HAL_UARTEx_SetTxFifoThreshold(&huart3, UART_TXFIFO_THRESHOLD_1_8) != HAL_OK)
  {
    Error_Handler();
  }
  if (HAL_UARTEx_SetRxFifoThreshold(&huart3, UART_RXFIFO_THRESHOLD_1_8) != HAL_OK)
  {
    Error_Handler();
  }
  if (HAL_UARTEx_DisableFifoMode(&huart3) != HAL_OK)
  {
    Error_Handler();
  }

}

static void MX_USART6_UART_Init(void)
{

  huart6.Instance = USART6;
  huart6.Init.BaudRate = 115200;
  huart6.Init.WordLength = UART_WORDLENGTH_8B;
  huart6.Init.StopBits = UART_STOPBITS_1;
  huart6.Init.Parity = UART_PARITY_NONE;
  huart6.Init.Mode = UART_MODE_TX_RX;
  huart6.Init.HwFlowCtl = UART_HWCONTROL_NONE;
  huart6.Init.OverSampling = UART_OVERSAMPLING_16;
  huart6.Init.OneBitSampling = UART_ONE_BIT_SAMPLE_DISABLE;
  huart6.Init.ClockPrescaler = UART_PRESCALER_DIV1;
  huart6.AdvancedInit.AdvFeatureInit = UART_ADVFEATURE_NO_INIT;
  if (HAL_UART_Init(&huart6) != HAL_OK)
  {
    Error_Handler();
  }
  if (HAL_UARTEx_SetTxFifoThreshold(&huart6, UART_TXFIFO_THRESHOLD_1_8) != HAL_OK)
  {
    Error_Handler();
  }
  if (HAL_UARTEx_SetRxFifoThreshold(&huart6, UART_RXFIFO_THRESHOLD_1_8) != HAL_OK)
  {
    Error_Handler();
  }
  if (HAL_UARTEx_EnableFifoMode(&huart6) != HAL_OK)
  {
    Error_Handler();
  }

}

static void MX_DMA_Init(void)
{

  /* DMA controller clock enable */
  __HAL_RCC_DMA1_CLK_ENABLE();

  /* DMA interrupt init */
  /* DMA1_Stream0_IRQn interrupt configuration */
  HAL_NVIC_SetPriority(DMA1_Stream0_IRQn, 0, 0);
  HAL_NVIC_EnableIRQ(DMA1_Stream0_IRQn);
  /* DMA1_Stream1_IRQn interrupt configuration */
  HAL_NVIC_SetPriority(DMA1_Stream1_IRQn, 0, 0);
  HAL_NVIC_EnableIRQ(DMA1_Stream1_IRQn);

}

static void MX_GPIO_Init(void)
{
  GPIO_InitTypeDef GPIO_InitStruct = {0};

  /* GPIO Ports Clock Enable */
  __HAL_RCC_GPIOE_CLK_ENABLE();
  __HAL_RCC_GPIOH_CLK_ENABLE();
  __HAL_RCC_GPIOC_CLK_ENABLE();
  __HAL_RCC_GPIOA_CLK_ENABLE();
  __HAL_RCC_GPIOB_CLK_ENABLE();
  __HAL_RCC_GPIOD_CLK_ENABLE();

  /*Configure GPIO pin Output Level */
  HAL_GPIO_WritePin(GPIOE, KICKMODE_Pin|BOOST_Pin, GPIO_PIN_RESET);

  /*Configure GPIO pin Output Level */
  HAL_GPIO_WritePin(GPIOD, ALIVE_Pin|POWER_Pin, GPIO_PIN_RESET);

  /*Configure GPIO pins : DONE_Pin KICK_Pin */
  GPIO_InitStruct.Pin = DONE_Pin|KICK_Pin;
  GPIO_InitStruct.Mode = GPIO_MODE_INPUT;
  GPIO_InitStruct.Pull = GPIO_NOPULL;
  HAL_GPIO_Init(GPIOE, &GPIO_InitStruct);

  /*Configure GPIO pins : KICKMODE_Pin BOOST_Pin */
  GPIO_InitStruct.Pin = KICKMODE_Pin|BOOST_Pin;
  GPIO_InitStruct.Mode = GPIO_MODE_OUTPUT_PP;
  GPIO_InitStruct.Pull = GPIO_NOPULL;
  GPIO_InitStruct.Speed = GPIO_SPEED_FREQ_LOW;
  HAL_GPIO_Init(GPIOE, &GPIO_InitStruct);

  /*Configure GPIO pins : DIPSW_1_Pin DIPSW_2_Pin */
  GPIO_InitStruct.Pin = DIPSW_1_Pin|DIPSW_2_Pin;
  GPIO_InitStruct.Mode = GPIO_MODE_INPUT;
  GPIO_InitStruct.Pull = GPIO_PULLUP;
  HAL_GPIO_Init(GPIOB, &GPIO_InitStruct);

  /*Configure GPIO pins : DIPSW_3_Pin DIPSW_4_Pin USER_SW0_Pin USER_SW1_Pin */
  GPIO_InitStruct.Pin = DIPSW_3_Pin|DIPSW_4_Pin|USER_SW0_Pin|USER_SW1_Pin;
  GPIO_InitStruct.Mode = GPIO_MODE_INPUT;
  GPIO_InitStruct.Pull = GPIO_PULLUP;
  HAL_GPIO_Init(GPIOD, &GPIO_InitStruct);

  /*Configure GPIO pin : EMO_Pin */
  GPIO_InitStruct.Pin = EMO_Pin;
  GPIO_InitStruct.Mode = GPIO_MODE_INPUT;
  GPIO_InitStruct.Pull = GPIO_NOPULL;
  HAL_GPIO_Init(EMO_GPIO_Port, &GPIO_InitStruct);

  /*Configure GPIO pins : ALIVE_Pin POWER_Pin */
  GPIO_InitStruct.Pin = ALIVE_Pin|POWER_Pin;
  GPIO_InitStruct.Mode = GPIO_MODE_OUTPUT_PP;
  GPIO_InitStruct.Pull = GPIO_NOPULL;
  GPIO_InitStruct.Speed = GPIO_SPEED_FREQ_LOW;
  HAL_GPIO_Init(GPIOD, &GPIO_InitStruct);

  /*Configure GPIO pins : PE0 PE1 */
  GPIO_InitStruct.Pin = GPIO_PIN_0|GPIO_PIN_1;
  GPIO_InitStruct.Mode = GPIO_MODE_AF_PP;
  GPIO_InitStruct.Pull = GPIO_NOPULL;
  GPIO_InitStruct.Speed = GPIO_SPEED_FREQ_LOW;
  GPIO_InitStruct.Alternate = GPIO_AF8_UART8;
  HAL_GPIO_Init(GPIOE, &GPIO_InitStruct);

}

void Error_Handler(void)
{
}

/************************ (C) COPYRIGHT STMicroelectronics *****END OF FILE****/
